# NAND register map
Registers from a debugger description file.
Registers are 32-bit, access not given, no defined reset value unless marked. A register's access mark holds for its fields unless they carry their own. Addresses are absolute; registers are grouped by the start of their names; lines under a group give offsets from that group; [hi:lo] are bit positions; {n}, {i} and the like mark numbered series; 'fields as' and 'values as' point back to an identical list; <NAME> marks a mode.

## SFR
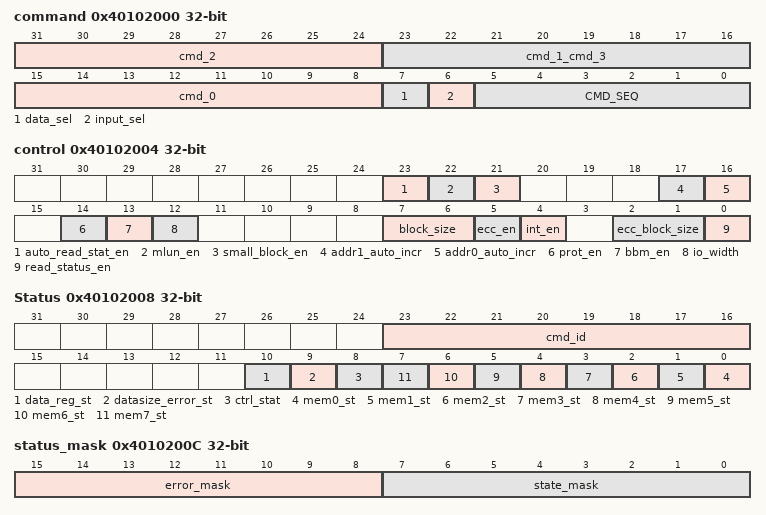
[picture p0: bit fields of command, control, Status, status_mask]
0x40102000 command
  [31:24] cmd_2, [23:16] cmd_1_cmd_3, [15:8] cmd_0, [7] data_sel, [6] input_sel, [5:0] CMD_SEQ
0x40102004 control
  [23] auto_read_stat_en, [22] mlun_en, [21] small_block_en, [17] addr1_auto_incr, [16] addr0_auto_incr, [14] prot_en, [13] bbm_en, [12] io_width, [7:6] block_size, [5] ecc_en, [4] int_en, [2:1] ecc_block_size, [0] read_status_en
0x40102008 Status ro
  [23:16] cmd_id, [10] data_reg_st, [9] datasize_error_st, [8] ctrl_stat, [n] mem{n}_st (n=0..7)
0x4010200C status_mask
  [15:8] error_mask, [7:0] state_mask
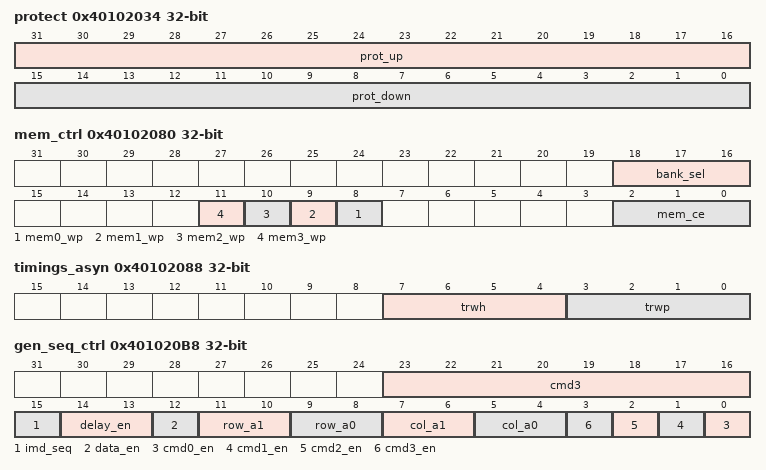
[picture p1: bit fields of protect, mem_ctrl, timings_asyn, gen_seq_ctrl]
0x40102034 protect
  [31:16] prot_up, [15:0] prot_down
0x40102074 bbm_ctrl
  [0] rmp_init
0x40102080 mem_ctrl
  [18:16] bank_sel, [n+8] mem{n}_wp (n=0..3), [2:0] mem_ce
0x40102088 timings_asyn
  [7:4] trwh, [3:0] trwp
0x401020B8 gen_seq_ctrl
  [23:16] cmd3, [15] imd_seq, [14:13] delay_en, [12] data_en, [11:10] row_a1, [9:8] row_a0, [7:6] col_a1, [5:4] col_a0, [n] cmd{n}_en (n=0..3)
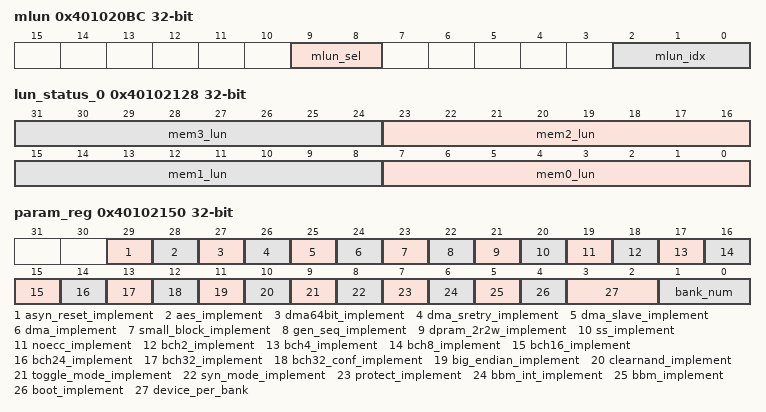
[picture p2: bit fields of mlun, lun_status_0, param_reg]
0x401020BC mlun
  [9:8] mlun_sel, [2:0] mlun_idx
0x40102124 cmd_mark wo
  [7:0] cmd_id
0x40102128 lun_status_0 ro
  [8n+7:8n] mem{n}_lun (n=0..3)
0x40102150 param_reg ro
  [29] asyn_reset_implement, [28] aes_implement, [27] dma64bit_implement, [26] dma_sretry_implement, [25] dma_slave_implement, [24] dma_implement, [23] small_block_implement, [22] gen_seq_implement, [21] dpram_2r2w_implement, [20] ss_implement, [19] noecc_implement, [18] bch2_implement, [17] bch4_implement, [16] bch8_implement, [15] bch16_implement, [14] bch24_implement, [13] bch32_implement, [12] bch32_conf_implement, [11] big_endian_implement, [10] clearnand_implement, [9] toggle_mode_implement, [8] syn_mode_implement, [7] protect_implement, [6] bbm_int_implement, [5] bbm_implement, [4] boot_implement, [3:2] device_per_bank, [1:0] bank_num

## int
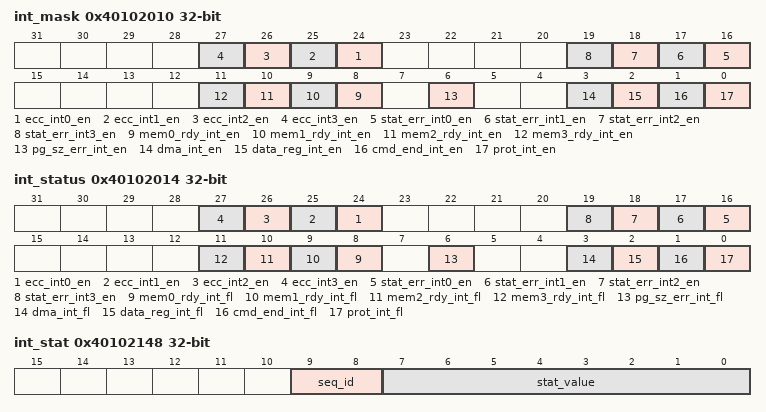
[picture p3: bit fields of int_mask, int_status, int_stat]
0x40102010 int_mask
  [n+24] ecc_int{n}_en (n=0..3), [n+16] stat_err_int{n}_en (n=0..3), [n+8] mem{n}_rdy_int_en (n=0..3), [6] pg_sz_err_int_en, [3] dma_int_en, [2] data_reg_int_en, [1] cmd_end_int_en, [0] prot_int_en
0x40102014 int_status
  [n+24] ecc_int{n}_en (n=0..3), [n+16] stat_err_int{n}_en (n=0..3), [n+8] mem{n}_rdy_int_fl (n=0..3), [6] pg_sz_err_int_fl, [3] dma_int_fl, [2] data_reg_int_fl, [1] cmd_end_int_fl, [0] prot_int_fl
0x40102148 int_stat
  [9:8] seq_id, [7:0] stat_value

## ecc
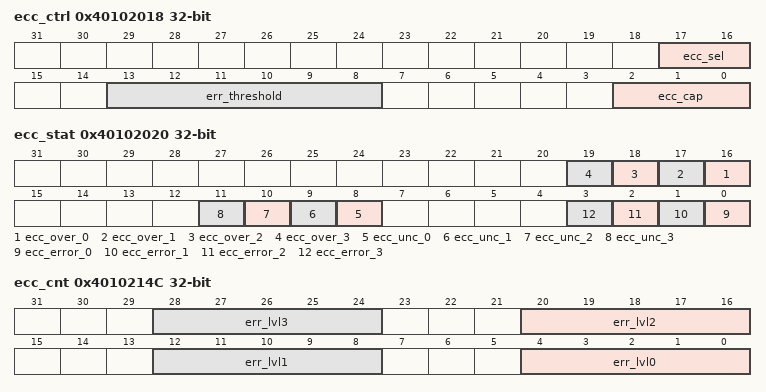
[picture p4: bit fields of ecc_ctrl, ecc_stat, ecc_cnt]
0x40102018 ecc_ctrl
  [17:16] ecc_sel, [13:8] err_threshold, [2:0] ecc_cap
0x4010201C ecc_offset
  [15:0] ecc_offset
0x40102020 ecc_stat
  [n+16] ecc_over_{n} (n=0..3), [n+8] ecc_unc_{n} (n=0..3), [n] ecc_error_{n} (n=0..3)
0x4010214C ecc_cnt
  [8n+4:8n] err_lvl{n} (n=0..3)

## addr0
0x40102024 addr0_col
  [15:0] addr0_col
0x40102028 addr0_row
  [23:0] addr0_row

## addr1
0x4010202C addr1_col
  [15:0] addr1_col
0x40102030 addr1_row
  [23:0] addr1_row

## fifo
0x40102038 fifo_data
0x401020B0 fifo_init
  [0] fifo_init
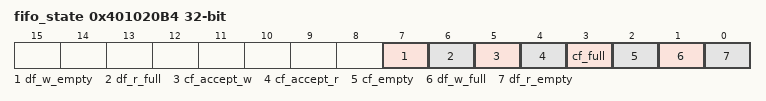
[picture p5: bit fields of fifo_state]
0x401020B4 fifo_state ro
  [7] df_w_empty, [6] df_r_full, [5] cf_accept_w, [4] cf_accept_r, [3] cf_full, [2] cf_empty, [1] df_w_full, [0] df_r_empty

## data
0x4010203C data_reg
0x40102040 data_reg_size
  [1:0] data_reg_size
0x40102084 data_size
  [14:0] data_size

## dev0
0x40102044 dev0_ptr
  [31:0] ptr_addr
0x401020C0 dev0_size
  [11:0] dev_size

## dev1
0x40102048 dev1_ptr
  [31:0] ptr_addr
0x401020C4 dev1_size
  [11:0] dev_size

## dev2
0x4010204C dev2_ptr
  [31:0] ptr_addr
0x401020C8 dev2_size
  [11:0] dev_size

## dev3
0x40102050 dev3_ptr
  [31:0] ptr_addr
0x401020CC dev3_size
  [11:0] dev_size

## dma
0x40102064 dma_addr
  [31:0] dma_addr_l
0x4010206C dma_cnt
  [31:0] cnt_init
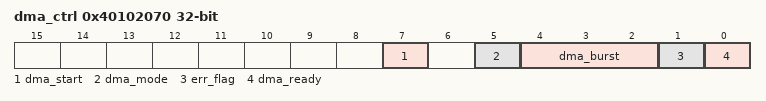
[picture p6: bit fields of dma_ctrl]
0x40102070 dma_ctrl
  [7] dma_start, [5] dma_mode, [4:2] dma_burst, [1] err_flag, [0] dma_ready
0x40102114 dma_tlvl
  [7:0] dma_tlvl

## time
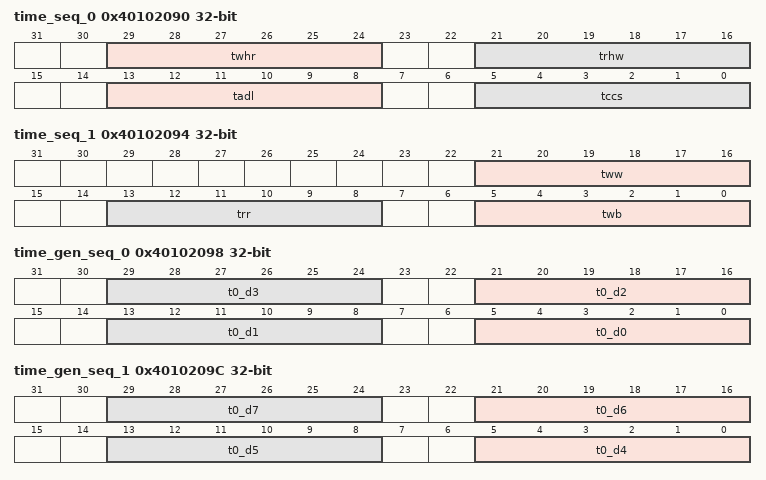
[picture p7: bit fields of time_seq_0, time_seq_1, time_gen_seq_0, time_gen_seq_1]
0x40102090 time_seq_0
  [29:24] twhr, [21:16] trhw, [13:8] tadl, [5:0] tccs
0x40102094 time_seq_1
  [21:16] tww, [13:8] trr, [5:0] twb
0x40102098 time_gen_seq_0
  [8n+5:8n] t0_d{n} (n=0..3)
0x4010209C time_gen_seq_1
  [8n-27:8n-32] t0_d{n} (n=4..7)
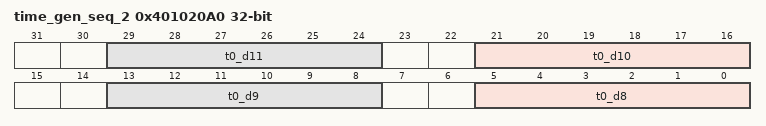
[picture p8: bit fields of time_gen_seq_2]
0x401020A0 time_gen_seq_2
  [8n-59:8n-64] t0_d{n} (n=8..11)
0x40102134 time_gen_seq_3
  [5:0] t0_d12
